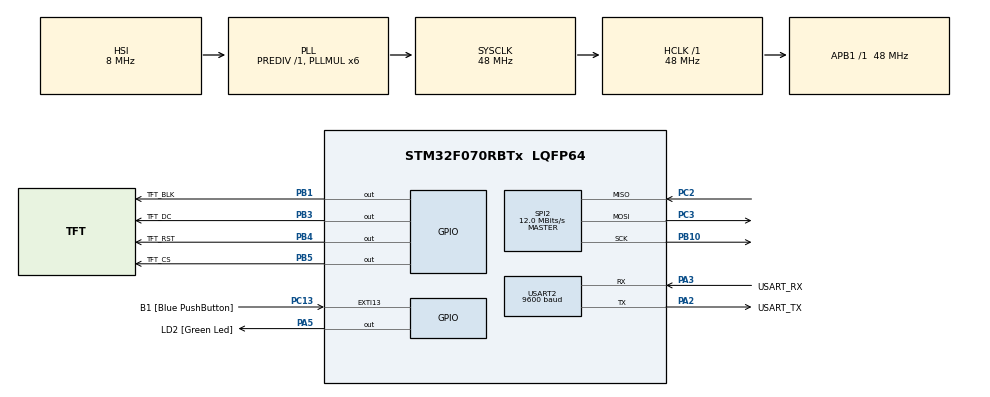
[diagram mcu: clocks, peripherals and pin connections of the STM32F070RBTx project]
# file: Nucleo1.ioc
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Mcu.Family=STM32F0
Mcu.Name=STM32F070RBTx
Mcu.Package=LQFP64
PA13.GPIO_Label=TMS
PA13.Mode=Serial_Wire
PA13.Signal=SYS_SWDIO
PA14.Mode=Serial_Wire
PA14.Signal=SYS_SWCLK
PA2.GPIO_Label=USART_TX
PA2.Mode=Asynchronous
PA2.Signal=USART2_TX
PA3.GPIO_Label=USART_RX
PA3.Mode=Asynchronous
PA3.Signal=USART2_RX
PA5.GPIO_Label=LD2 [Green Led]
PA5.Signal=GPIO_Output
PB1.GPIO_Label=TFT_BLK
PB1.Signal=GPIO_Output
PB10.Mode=Full_Duplex_Master
PB10.Signal=SPI2_SCK
PB3.GPIO_Label=TFT_DC
PB3.Signal=GPIO_Output
PB4.GPIO_Label=TFT_RST
PB4.Signal=GPIO_Output
PB5.GPIO_Label=TFT_CS
PB5.Signal=GPIO_Output
PC13.GPIO_Label=B1 [Blue PushButton]
PC13.GPIO_ModeDefaultEXTI=GPIO_MODE_IT_FALLING
PC13.Signal=GPXTI13
PC14-OSC32_IN.GPIO_Label=RCC_OSC32_IN
PC14-OSC32_IN.Mode=LSE-External-Oscillator
PC14-OSC32_IN.Signal=RCC_OSC32_IN
PC15-OSC32_OUT.GPIO_Label=RCC_OSC32_OUT
PC15-OSC32_OUT.Mode=LSE-External-Oscillator
PC15-OSC32_OUT.Signal=RCC_OSC32_OUT
PC2.Mode=Full_Duplex_Master
PC2.Signal=SPI2_MISO
PC3.Mode=Full_Duplex_Master
PC3.Signal=SPI2_MOSI
PF0-OSC_IN.GPIO_Label=RCC_OSC_IN
PF0-OSC_IN.Signal=RCC_OSC_IN
ProjectManager.HeapSize=0x200
ProjectManager.StackSize=0x400
ProjectManager.TargetToolchain=EWARM V8.32
RCC.AHBFreq_Value=48000000
RCC.APB1Freq_Value=48000000
RCC.APB1TimFreq_Value=48000000
RCC.HCLKFreq_Value=48000000
RCC.PLLMUL=RCC_PLL_MUL6
RCC.SYSCLKFreq_VALUE=48000000
RCC.SYSCLKSource=RCC_SYSCLKSOURCE_PLLCLK
SPI2.BaudRatePrescaler=SPI_BAUDRATEPRESCALER_4
SPI2.CalculateBaudRate=12.0 MBits/s
SPI2.DataSize=SPI_DATASIZE_8BIT
SPI2.Direction=SPI_DIRECTION_2LINES
SPI2.Mode=SPI_MODE_MASTER
SPI2.VirtualType=VM_MASTER
USART2.BaudRate=9600
USART2.VirtualMode-Asynchronous=VM_ASYNC
board=NUCLEO-F070RB

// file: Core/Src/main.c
/* USER CODE BEGIN Header */
/**
  ******************************************************************************
  * @file           : main.c
  * @brief          : Main program body
  ******************************************************************************
  * @attention
  *
  * Copyright (c) 2023 STMicroelectronics.
  * All rights reserved.
  *
  * This software is licensed under terms that can be found in the LICENSE file
  * in the root directory of this software component.
  * If no LICENSE file comes with this software, it is provided AS-IS.
  *
  ******************************************************************************
  */
/* USER CODE END Header */
#include "main.h"

/* USER CODE BEGIN Includes */
#include "../Inc/CG9A01.h"
/* USER CODE END Includes */

SPI_HandleTypeDef hspi2;

UART_HandleTypeDef huart2;

/* USER CODE BEGIN PV */
// Global flags
volatile uint8_t spi_xmit_flag = 0;
volatile uint8_t spi_recv_flag = 0;

/* USER CODE END PV */

void SystemClock_Config(void);
static void MX_GPIO_Init(void);
static void MX_SPI2_Init(void);
static void MX_USART2_UART_Init(void);
/* USER CODE BEGIN PFP */
// This is called when SPI transmit is done
/* USER CODE END PFP */

int main(void)
{

  /* MCU Configuration--------------------------------------------------------*/

  /* Reset of all peripherals, Initializes the Flash interface and the Systick. */
  HAL_Init();

  /* Configure the system clock */
  SystemClock_Config();

  /* Initialize all configured peripherals */
  MX_GPIO_Init();
  MX_SPI2_Init();
  MX_USART2_UART_Init();
  /* USER CODE BEGIN 2 */
  //HAL_StatusTypeDef UARTRcvStat ;
  //HAL_StatusTypeDef SPIRcvStat ;
  LCD_Init();
  /* USER CODE END 2 */
  HAL_GPIO_WritePin(TFT_BLK_GPIO_Port, TFT_BLK_Pin, GPIO_PIN_SET);
  /* Infinite loop */
  while (1)
  {

    LCD_Fill(WHITE);
    LCD_Fill(LBBLUE);
    LCD_Fill(LIGHTGREEN);
    LCD_Fill(DARKBLUE);
    LCD_Fill(BRRED);
    LCD_Fill(YELLOW);
    LCD_Fill(GREEN);
    LCD_Fill(RED);
    LCD_Fill(GRED);
  }
}

void SystemClock_Config(void)
{
  RCC_OscInitTypeDef RCC_OscInitStruct = {0};
  RCC_ClkInitTypeDef RCC_ClkInitStruct = {0};

  /** Initializes the RCC Oscillators according to the specified parameters
  * in the RCC_OscInitTypeDef structure.
  */
  RCC_OscInitStruct.OscillatorType = RCC_OSCILLATORTYPE_HSI;
  RCC_OscInitStruct.HSIState = RCC_HSI_ON;
  RCC_OscInitStruct.HSICalibrationValue = RCC_HSICALIBRATION_DEFAULT;
  RCC_OscInitStruct.PLL.PLLState = RCC_PLL_ON;
  RCC_OscInitStruct.PLL.PLLSource = RCC_PLLSOURCE_HSI;
  RCC_OscInitStruct.PLL.PLLMUL = RCC_PLL_MUL6;
  RCC_OscInitStruct.PLL.PREDIV = RCC_PREDIV_DIV1;
  if (HAL_RCC_OscConfig(&RCC_OscInitStruct) != HAL_OK)
  {
    Error_Handler();
  }

  /** Initializes the CPU, AHB and APB buses clocks
  */
  RCC_ClkInitStruct.ClockType = RCC_CLOCKTYPE_HCLK|RCC_CLOCKTYPE_SYSCLK
                              |RCC_CLOCKTYPE_PCLK1;
  RCC_ClkInitStruct.SYSCLKSource = RCC_SYSCLKSOURCE_PLLCLK;
  RCC_ClkInitStruct.AHBCLKDivider = RCC_SYSCLK_DIV1;
  RCC_ClkInitStruct.APB1CLKDivider = RCC_HCLK_DIV1;

  if (HAL_RCC_ClockConfig(&RCC_ClkInitStruct, FLASH_LATENCY_1) != HAL_OK)
  {
    Error_Handler();
  }
}

static void MX_SPI2_Init(void)
{

  /* SPI2 parameter configuration*/
  hspi2.Instance = SPI2;
  hspi2.Init.Mode = SPI_MODE_MASTER;
  hspi2.Init.Direction = SPI_DIRECTION_2LINES;
  hspi2.Init.DataSize = SPI_DATASIZE_8BIT;
  hspi2.Init.CLKPolarity = SPI_POLARITY_LOW;
  hspi2.Init.CLKPhase = SPI_PHASE_1EDGE;
  hspi2.Init.NSS = SPI_NSS_SOFT;
  hspi2.Init.BaudRatePrescaler = SPI_BAUDRATEPRESCALER_4;
  hspi2.Init.FirstBit = SPI_FIRSTBIT_MSB;
  hspi2.Init.TIMode = SPI_TIMODE_DISABLE;
  hspi2.Init.CRCCalculation = SPI_CRCCALCULATION_DISABLE;
  hspi2.Init.CRCPolynomial = 7;
  hspi2.Init.CRCLength = SPI_CRC_LENGTH_DATASIZE;
  hspi2.Init.NSSPMode = SPI_NSS_PULSE_ENABLE;
  if (HAL_SPI_Init(&hspi2) != HAL_OK)
  {
    Error_Handler();
  }

}

static void MX_USART2_UART_Init(void)
{

  huart2.Instance = USART2;
  huart2.Init.BaudRate = 9600;
  huart2.Init.WordLength = UART_WORDLENGTH_8B;
  huart2.Init.StopBits = UART_STOPBITS_1;
  huart2.Init.Parity = UART_PARITY_NONE;
  huart2.Init.Mode = UART_MODE_TX_RX;
  huart2.Init.HwFlowCtl = UART_HWCONTROL_NONE;
  huart2.Init.OverSampling = UART_OVERSAMPLING_16;
  huart2.Init.OneBitSampling = UART_ONE_BIT_SAMPLE_DISABLE;
  huart2.AdvancedInit.AdvFeatureInit = UART_ADVFEATURE_NO_INIT;
  if (HAL_UART_Init(&huart2) != HAL_OK)
  {
    Error_Handler();
  }

}

static void MX_GPIO_Init(void)
{
  GPIO_InitTypeDef GPIO_InitStruct = {0};

  /* GPIO Ports Clock Enable */
  __HAL_RCC_GPIOC_CLK_ENABLE();
  __HAL_RCC_GPIOF_CLK_ENABLE();
  __HAL_RCC_GPIOA_CLK_ENABLE();
  __HAL_RCC_GPIOB_CLK_ENABLE();

  /*Configure GPIO pin Output Level */
  HAL_GPIO_WritePin(LD2_GPIO_Port, LD2_Pin, GPIO_PIN_RESET);

  /*Configure GPIO pin Output Level */
  HAL_GPIO_WritePin(GPIOB, TFT_BLK_Pin|TFT_DC_Pin|TFT_RST_Pin|TFT_CS_Pin, GPIO_PIN_RESET);

  /*Configure GPIO pin : B1_Pin */
  GPIO_InitStruct.Pin = B1_Pin;
  GPIO_InitStruct.Mode = GPIO_MODE_IT_FALLING;
  GPIO_InitStruct.Pull = GPIO_NOPULL;
  HAL_GPIO_Init(B1_GPIO_Port, &GPIO_InitStruct);

  /*Configure GPIO pin : LD2_Pin */
  GPIO_InitStruct.Pin = LD2_Pin;
  GPIO_InitStruct.Mode = GPIO_MODE_OUTPUT_PP;
  GPIO_InitStruct.Pull = GPIO_NOPULL;
  GPIO_InitStruct.Speed = GPIO_SPEED_FREQ_LOW;
  HAL_GPIO_Init(LD2_GPIO_Port, &GPIO_InitStruct);

  /*Configure GPIO pins : TFT_BLK_Pin TFT_DC_Pin TFT_RST_Pin TFT_CS_Pin */
  GPIO_InitStruct.Pin = TFT_BLK_Pin|TFT_DC_Pin|TFT_RST_Pin|TFT_CS_Pin;
  GPIO_InitStruct.Mode = GPIO_MODE_OUTPUT_PP;
  GPIO_InitStruct.Pull = GPIO_NOPULL;
  GPIO_InitStruct.Speed = GPIO_SPEED_FREQ_LOW;
  HAL_GPIO_Init(GPIOB, &GPIO_InitStruct);

}

void Error_Handler(void)
{
  __disable_irq();
  while (1)
  {
  }
}
